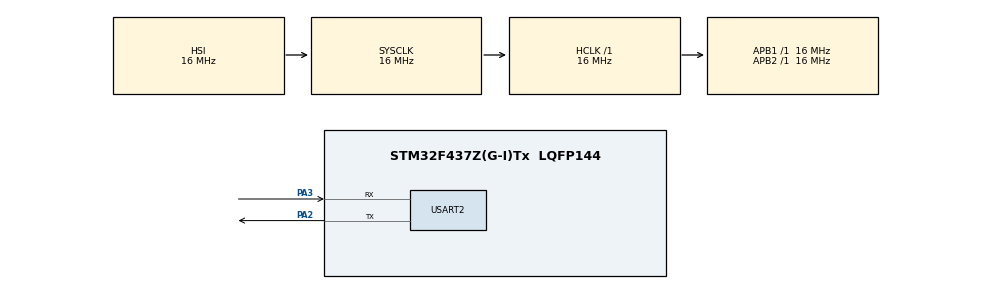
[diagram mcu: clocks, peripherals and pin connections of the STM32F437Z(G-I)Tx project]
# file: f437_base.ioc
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FREERTOS.Tasks01=Sensor,24,128,StartSensor,Default,NULL,Static,SensorBuffer,SensorControlBlock;Telemetry,8,128,StartTelemetry,Default,NULL,Static,TelemetryBuffer,TelemetryControlBlock;Ejection,16,128,StartEjection,Default,NULL,Static,EjectionBuffer,EjectionControlBlock
FREERTOS.configUSE_NEWLIB_REENTRANT=1
Mcu.Family=STM32F4
Mcu.Name=STM32F437Z(G-I)Tx
Mcu.Package=LQFP144
NVIC.PriorityGroup=NVIC_PRIORITYGROUP_4
NVIC.TIM6_DAC_IRQn=true\:15\:0\:false\:false\:true\:false\:false\:true
NVIC.TimeBase=TIM6_DAC_IRQn
NVIC.TimeBaseIP=TIM6
PA2.Mode=Asynchronous
PA2.Signal=USART2_TX
PA3.Mode=Asynchronous
PA3.Signal=USART2_RX
ProjectManager.HeapSize=0x200
ProjectManager.StackSize=0x400
ProjectManager.TargetToolchain=STM32CubeIDE
RCC.AHBFreq_Value=16000000
RCC.APB1Freq_Value=16000000
RCC.APB2Freq_Value=16000000
RCC.CortexFreq_Value=16000000
RCC.HSE_VALUE=25000000
RCC.HSI_VALUE=16000000
RCC.LSE_VALUE=32768
RCC.SYSCLKFreq_VALUE=16000000
RCC.VCOOutputFreq_Value=192000000
USART2.VirtualMode=VM_ASYNC
VP_FREERTOS_VS_CMSIS_V2.Mode=CMSIS_V2
VP_SYS_VS_tim6.Mode=TIM6
board=custom

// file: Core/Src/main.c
/* USER CODE BEGIN Header */
/**
 ******************************************************************************
 * @file           : main.c
 * @brief          : Main program body
 ******************************************************************************
 * @attention
 *
 * <h2><center>&copy; Copyright (c) 2021 STMicroelectronics.
 * All rights reserved.</center></h2>
 *
 * This software component is licensed by ST under Ultimate Liberty license
 * SLA0044, the "License"; You may not use this file except in compliance with
 * the License. You may obtain a copy of the License at:
 *                             www.st.com/SLA0044
 *
 ******************************************************************************
 */
/* USER CODE END Header */
#include "main.h"
#include "cmsis_os.h"

/* USER CODE BEGIN Includes */
#include <string.h>
#include <stdio.h>
/* USER CODE END Includes */

typedef StaticTask_t osStaticThreadDef_t;

UART_HandleTypeDef huart2;

/* Definitions for Sensor */
osThreadId_t SensorHandle;
uint32_t SensorBuffer[ 128 ];
osStaticThreadDef_t SensorControlBlock;
const osThreadAttr_t Sensor_attributes = {
  .name = "Sensor",
  .cb_mem = &SensorControlBlock,
  .cb_size = sizeof(SensorControlBlock),
  .stack_mem = &SensorBuffer[0],
  .stack_size = sizeof(SensorBuffer),
  .priority = (osPriority_t) osPriorityNormal,
};
/* Definitions for Telemetry */
osThreadId_t TelemetryHandle;
uint32_t TelemetryBuffer[ 128 ];
osStaticThreadDef_t TelemetryControlBlock;
const osThreadAttr_t Telemetry_attributes = {
  .name = "Telemetry",
  .cb_mem = &TelemetryControlBlock,
  .cb_size = sizeof(TelemetryControlBlock),
  .stack_mem = &TelemetryBuffer[0],
  .stack_size = sizeof(TelemetryBuffer),
  .priority = (osPriority_t) osPriorityLow,
};
/* Definitions for Ejection */
osThreadId_t EjectionHandle;
uint32_t EjectionBuffer[ 128 ];
osStaticThreadDef_t EjectionControlBlock;
const osThreadAttr_t Ejection_attributes = {
  .name = "Ejection",
  .cb_mem = &EjectionControlBlock,
  .cb_size = sizeof(EjectionControlBlock),
  .stack_mem = &EjectionBuffer[0],
  .stack_size = sizeof(EjectionBuffer),
  .priority = (osPriority_t) osPriorityBelowNormal,
};
/* USER CODE BEGIN PV */
// rtc variables
//RTC_DateTypeDef sdatestructureget;
//RTC_TimeTypeDef stimestructureget;
//RTC_AlarmTypeDef sAlarmA;
//RTC_AlarmTypeDef sAlarmB;

// flag to indicate alarmA interrupt occurred
volatile uint8_t alarmAOccurred = 0;
char msg[100];

float acceleration;
uint32_t numberOfFriends = 0; // :(
/* USER CODE END PV */

void SystemClock_Config(void);
static void MX_GPIO_Init(void);
static void MX_USART2_UART_Init(void);
void StartSensor(void *argument);
void StartTelemetry(void *argument);
void StartEjection(void *argument);

/* USER CODE BEGIN PFP */
void myprintf(char *buffer) {
	HAL_UART_Transmit(&huart2, (uint8_t*) buffer, 100, 100);
}
/* USER CODE END PFP */

int main(void)
{

  /* MCU Configuration--------------------------------------------------------*/

  /* Reset of all peripherals, Initializes the Flash interface and the Systick. */
  HAL_Init();

  /* Configure the system clock */
  SystemClock_Config();

  /* Initialize all configured peripherals */
  MX_GPIO_Init();
  MX_USART2_UART_Init();

  /* Init scheduler */
  osKernelInitialize();

  /* Create the thread(s) */
  /* creation of Sensor */
  SensorHandle = osThreadNew(StartSensor, NULL, &Sensor_attributes);

  /* creation of Telemetry */
  TelemetryHandle = osThreadNew(StartTelemetry, NULL, &Telemetry_attributes);

  /* creation of Ejection */
  EjectionHandle = osThreadNew(StartEjection, NULL, &Ejection_attributes);

  /* Start scheduler */
  osKernelStart();

  /* We should never get here as control is now taken by the scheduler */
  /* Infinite loop */
	while (1) {

	}
}

void SystemClock_Config(void)
{
  RCC_OscInitTypeDef RCC_OscInitStruct = {0};
  RCC_ClkInitTypeDef RCC_ClkInitStruct = {0};

  /** Configure the main internal regulator output voltage
  */
  __HAL_RCC_PWR_CLK_ENABLE();
  __HAL_PWR_VOLTAGESCALING_CONFIG(PWR_REGULATOR_VOLTAGE_SCALE3);
  /** Initializes the RCC Oscillators according to the specified parameters
  * in the RCC_OscInitTypeDef structure.
  */
  RCC_OscInitStruct.OscillatorType = RCC_OSCILLATORTYPE_HSI;
  RCC_OscInitStruct.HSIState = RCC_HSI_ON;
  RCC_OscInitStruct.HSICalibrationValue = RCC_HSICALIBRATION_DEFAULT;
  RCC_OscInitStruct.PLL.PLLState = RCC_PLL_NONE;
  if (HAL_RCC_OscConfig(&RCC_OscInitStruct) != HAL_OK)
  {
    Error_Handler();
  }
  /** Initializes the CPU, AHB and APB buses clocks
  */
  RCC_ClkInitStruct.ClockType = RCC_CLOCKTYPE_HCLK|RCC_CLOCKTYPE_SYSCLK
                              |RCC_CLOCKTYPE_PCLK1|RCC_CLOCKTYPE_PCLK2;
  RCC_ClkInitStruct.SYSCLKSource = RCC_SYSCLKSOURCE_HSI;
  RCC_ClkInitStruct.AHBCLKDivider = RCC_SYSCLK_DIV1;
  RCC_ClkInitStruct.APB1CLKDivider = RCC_HCLK_DIV1;
  RCC_ClkInitStruct.APB2CLKDivider = RCC_HCLK_DIV1;

  if (HAL_RCC_ClockConfig(&RCC_ClkInitStruct, FLASH_LATENCY_0) != HAL_OK)
  {
    Error_Handler();
  }
}

static void MX_USART2_UART_Init(void)
{

  huart2.Instance = USART2;
  huart2.Init.BaudRate = 115200;
  huart2.Init.WordLength = UART_WORDLENGTH_8B;
  huart2.Init.StopBits = UART_STOPBITS_1;
  huart2.Init.Parity = UART_PARITY_NONE;
  huart2.Init.Mode = UART_MODE_TX_RX;
  huart2.Init.HwFlowCtl = UART_HWCONTROL_NONE;
  huart2.Init.OverSampling = UART_OVERSAMPLING_16;
  if (HAL_UART_Init(&huart2) != HAL_OK)
  {
    Error_Handler();
  }

}

static void MX_GPIO_Init(void)
{

  /* GPIO Ports Clock Enable */
  __HAL_RCC_GPIOA_CLK_ENABLE();

}

void StartSensor(void *argument)
{
  /* USER CODE BEGIN 5 */
	float accels[10] = { 0.0, 0.23, 120.0, 420.0, 69.42, 10.3, 20.5, 12.12,
			42.42, 0.0 };
	uint32_t friends[10] = { 0, 1, 2, 3, 4, 5, 4, 3, 2, 1 };
	/* Infinite loop */
	uint32_t i = 0;
	char *buffer = (char*) malloc(100);
	memset(buffer, 0, 100);
	for (;;) {

//		acceleration = accels[i % 10];
//		numberOfFriends = friends[i % 10];
//		sprintf(buffer, "IN Acceleration: %f\r\n", acceleration);
//		myprintf(buffer);
//		sprintf(buffer, "IN Number of friends: %lu\r\n", numberOfFriends);
//		myprintf(buffer);
		++i;
		sprintf(buffer, "1\r\n");
		myprintf(buffer);
		osDelay(2000);

	}
  /* USER CODE END 5 */
}

void StartTelemetry(void *argument)
{
  /* USER CODE BEGIN StartTelemetry */
	char* buffer = (char*) malloc(100);
	sprintf(buffer, "OUT Acceleration");
	memset(buffer, 0, 100);
	for (;;) {

		sprintf(buffer, "OUT Acceleration: %f\r\n", acceleration);
		myprintf(buffer);
		sprintf(buffer, "OUT Number of friends: %li\r\n", numberOfFriends);
		myprintf(buffer);
		osDelay(1000);

	}
  /* USER CODE END StartTelemetry */
}

void StartEjection(void *argument)
{
  /* USER CODE BEGIN StartEjection */
	char *buffer = (char*) malloc(100);
	sprintf(buffer, "OUT Acceleration");
	memset(buffer, 0, 100);
	for (;;) {

		if (numberOfFriends == 5) {
			sprintf(buffer, "EJECT or smthg\r\n");
			myprintf(buffer);
		}
		osDelay(1000);

	}
  /* USER CODE END StartEjection */
}

void HAL_TIM_PeriodElapsedCallback(TIM_HandleTypeDef *htim)
{
  if (htim->Instance == TIM6) {
    HAL_IncTick();
  }
}

void Error_Handler(void)
{
	__disable_irq();
	while (1) {
	}
}

/************************ (C) COPYRIGHT STMicroelectronics *****END OF FILE****/
